VERSION ""

NS_ :

BS_:

BU_: XXX DSU HCU EPS IPAS XX

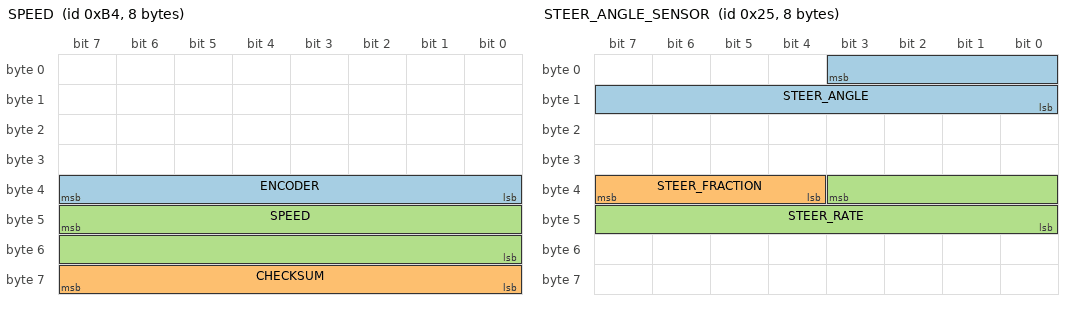
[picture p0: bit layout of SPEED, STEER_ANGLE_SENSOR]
BO_ 180 SPEED: 8 XXX
 SG_ ENCODER : 39|8@0+ (1,0) [0|255] "" XXX
 SG_ CHECKSUM : 63|8@0+ (1,0) [0|255] "" XXX
 SG_ SPEED : 47|16@0+ (0.01,0) [0|250] "kph" XXX

BO_ 560 BRAKE_MODULE2: 7 XXX
 SG_ BRAKE_PRESSED : 26|1@0+ (1,0) [0|1] "" XXX

BO_ 37 STEER_ANGLE_SENSOR: 8 XXX
 SG_ STEER_ANGLE : 3|12@0- (1.5,0) [-500|500] "deg" XXX
 SG_ STEER_FRACTION : 39|4@0- (0.1,0) [-0.7|0.7] "deg" XXX
 SG_ STEER_RATE : 35|12@0- (1,0) [-2000|2000] "deg/s" XXX

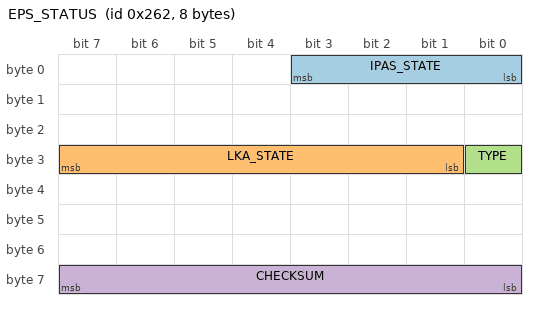
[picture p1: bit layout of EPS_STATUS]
BO_ 610 EPS_STATUS: 8 EPS
 SG_ IPAS_STATE : 3|4@0+ (1,0) [0|15] "" XXX
 SG_ LKA_STATE : 31|7@0+ (1,0) [0|127] "" XXX
 SG_ TYPE : 24|1@0+ (1,0) [0|1] "" XXX
 SG_ CHECKSUM : 63|8@0+ (1,0) [0|255] "" XXX

BO_ 177 SPEED_1: 8 XXX
 SG_ SPEED : 7|16@0+ (1,0) [0|250] "" XXX
 SG_ CHECKSUM : 40|8@1+ (1,0) [0|255] "" XXX

BO_ 179 SPEED_2: 8 XXX
 SG_ SPEED : 7|16@0+ (1,0) [0|255] "" XXX
 SG_ CHECKSUM : 47|8@0+ (1,0) [0|255] "" XXX

CM_ SG_ 36 ACCEL_Y "unit is tbd";
CM_ SG_ 36 YAW_RATE "verify";
CM_ SG_ 36 STEERING_TORQUE "does not seem the steer torque, tbd";
CM_ SG_ 466 ACCEL_NET "net acceleration produced by the system, given ACCEL_CMD, road grade and other factors";
CM_ SG_ 560 BRAKE_PRESSED "another brake pressed?";
CM_ SG_ 614 ANGLE "set to measured angle when ipas control isn't active";
CM_ SG_ 37 STEER_FRACTION "1/15th of the signal STEER_ANGLE, which is 1.5 deg; note that 0x8 is never set";
CM_ SG_ 37 STEER_RATE "factor is tbd";
CM_ SG_ 467 LOW_SPEED_LOCKOUT "in low speed lockout, system would always disengage below 28mph";
CM_ SG_ 467 SET_SPEED "43 kph are shown as 28mph, so conversion isnt perfect";
CM_ SG_ 921 UI_SET_SPEED "set speed shown in UI with user set unit";
CM_ SG_ 951 BRAKE_LIGHTS_ACC "brake lights when ACC commands decel";
CM_ SG_ 1042 REPEATED_BEEPS "recommended for fcw and other important alerts";
CM_ SG_ 550 BRAKE_PRESSURE "seems prop to pedal force";
CM_ SG_ 550 BRAKE_POSITION "seems proportional to pedal displacement, unclear the max value of 0x1c8";
CM_ SG_ 581 GAS_PEDAL "it seems slightly filtered";
CM_ SG_ 610 TYPE "seems 1 on Corolla, 0 on all others";
CM_ SG_ 1083 STATE "when the dashboard button is pressed, the value changes from zero to non-zero";
VAL_ 466 CRUISE_STATE 8 "active" 7 "standstill" 1 "off" ;
VAL_ 614 STATE 3 "enabled" 1 "disabled" ;
VAL_ 614 DIRECTION_CMD 3 "right" 2 "center" 1 "left" ;
VAL_ 1556 TURN_SIGNALS 3 "none" 2 "right" 1 "left" ;
VAL_ 467 LOW_SPEED_LOCKOUT 2 "low speed locked" 1 "ok" ;
VAL_ 921 CRUISE_CONTROL_STATE 2 "disabled" 11 "hold" 10 "hold_waiting_user_cmd" 6 "enabled" 5 "faulted" ;
VAL_ 1042 BARRIERS 3 "both" 2 "right" 1 "left" 0 "none" ;
VAL_ 1042 RIGHT_LINE 3 "orange" 2 "double" 1 "solid" 0 "none" ;
VAL_ 1042 LEFT_LINE 3 "orange" 2 "double" 1 "solid" 0 "none" ;
VAL_ 1042 LDA_ALERT 3 "hold with continuous beep" 2 "LDA unavailable" 1 "hold" 0 "none" ;
VAL_ 1553 UNITS 1 "km" 2 "miles" ;
VAL_ 610 IPAS_STATE 5 "override" 3 "enabled" 1 "disabled" ;
VAL_ 610 LKA_STATE 25 "temporary_fault" 9 "temporary_fault2" 5 "active" 1 "standby" ;
CM_ "AUTOGENERATED FILE, DO NOT EDIT"
CM_ "Imported file _comma.dbc starts her";
CM_ "Imported file _comma.dbc starts here
CM_ "Imported file _comma.dbc starts here";
CM_ "Imported file _comma.dbc starts here"
BO_ 359 STEERING_IPAS_COMMA: 8 IPAS
SG_ STATE : 7|4@0+ (1,0) [0|15] "" X";
CM_ "Imported file _toyota_2017.dbc starts here"
VERSION ";
CM_ "CHFFR_METRIC 37 STEER_ANGLE STEER_ANGLE 0.36 180";
CM_ "toyota_prius_2017_pt.dbc starts here"
BO_ 295 GEAR_PACKET: 8 XXX
SG_ CAR_MOVEMENT : 39|8@0- (1,0) [0|255] "" X";
